AUTOSAR XML (schema 00047)
package /Components
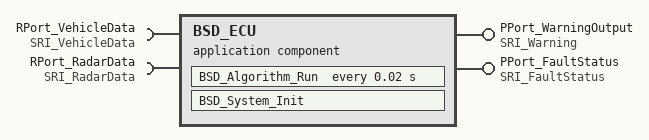
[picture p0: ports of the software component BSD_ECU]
  application sw component type BSD_ECU
    require port RPort_VehicleData: required-interface=SRI_VehicleData
      required-com-specs:
        data-element=Gear_Position, init-value=0
        data-element=Vehicle_Speed, init-value=0
        data-element=Turn_Signal, init-value=0
        data-element=Steering_Angle, init-value=0
    require port RPort_RadarData: required-interface=SRI_RadarData
      required-com-specs:
        data-element=Distance_Left, init-value=0
        data-element=Distance_Right, init-value=0
        data-element=Status_Left, init-value=0
        data-element=Status_Right, init-value=0
    provide port PPort_WarningOutput: provided-com-specs=[{data-element=Warning_Status, init-value=0}, {data-element=LED_Output, init-value=0}], provided-interface=SRI_Warning
    provide port PPort_FaultStatus: provided-com-specs=[{data-element=Sensor_L_Fault, init-value=0}, {data-element=Sensor_R_Fault, init-value=0}], provided-interface=SRI_FaultStatus
    behavior BSD_System_IB: handle-termination-and-restart=NO-SUPPORT
      timing event Time_20ms: start-on-event=BSD_Algorithm_Run, period=0.02
      runnable BSD_System_Init
      runnable BSD_Algorithm_Run
        data-read-access:
          8 x access:
            IN_RPort_RadarData_Distance_Left: accessed-variable=RPort_RadarData.Distance_Left
            IN_RPort_RadarData_Distance_Right: accessed-variable=RPort_RadarData.Distance_Right
            IN_RPort_VehicleData_Gear_Position: accessed-variable=RPort_VehicleData.Gear_Position
            IN_RPort_RadarData_Status_Left: accessed-variable=RPort_RadarData.Status_Left
            IN_RPort_RadarData_Status_Right: accessed-variable=RPort_RadarData.Status_Right
            IN_RPort_VehicleData_Steering_Angle: accessed-variable=RPort_VehicleData.Steering_Angle
            IN_RPort_VehicleData_Turn_Signal: accessed-variable=RPort_VehicleData.Turn_Signal
            IN_RPort_VehicleData_Vehicle_Speed: accessed-variable=RPort_VehicleData.Vehicle_Speed
        data-write-access:
          4 x access:
            OUT_PPort_WarningOutput_Warning_Status: accessed-variable=PPort_WarningOutput.Warning_Status
            OUT_PPort_WarningOutput_LED_Output: accessed-variable=PPort_WarningOutput.LED_Output
            OUT_PPort_FaultStatus_Sensor_L_Fault: accessed-variable=PPort_FaultStatus.Sensor_L_Fault
            OUT_PPort_FaultStatus_Sensor_R_Fault: accessed-variable=PPort_FaultStatus.Sensor_R_Fault
